AUTOSAR XML (schema 4-2-2)
package /Components
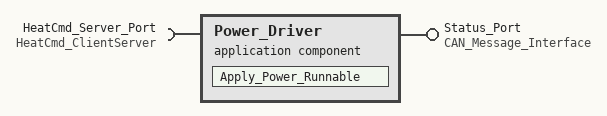
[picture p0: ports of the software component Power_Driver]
  application sw component type Power_Driver
    provide port Status_Port: provided-interface=CAN_Message_Interface
    require port HeatCmd_Server_Port: required-interface=HeatCmd_ClientServer
    behavior Power_Driver_Behavior
      data write completed event HW_Drive_Completed: start-on-event=Read_Sensors_Runnable, event-source=Status_Var_Access
      operation invoked event Power_Command_Invoked: start-on-event=Read_Sensors_Runnable, operation=Status_Port.setLevel
      transformer hard error event Driver_Hardware_Fault: start-on-event=Read_Sensors_Runnable, operation=Status_Port.reportFault
      runnable Apply_Power_Runnable: minimum-start-interval=20, symbol=Power_Driver::Apply_Power_Runnable
        data-send-points:
          access Status_Var_Access: accessed-variable=Status_Port.PowerDriverStatus
        sync call HeatCmd_ServerCall: operation=HeatCmd_Server_Port.setLevel, timeout=50
